# ATxmega384C3 device description
Architecture: AVR8_XMEGA; Family: AVR XMEGA
Registers are 8-bit, access not given, no defined reset value unless marked. A register's access mark holds for its fields unless they carry their own. Offsets are from the block's base; [hi:lo] are bit positions; lines under a group give offsets from that group; {n}, {i} and the like mark numbered series; 'fields as' and 'values as' point back to an identical list.

## DMA — DMA Controller
Instances: DMA 0x0100
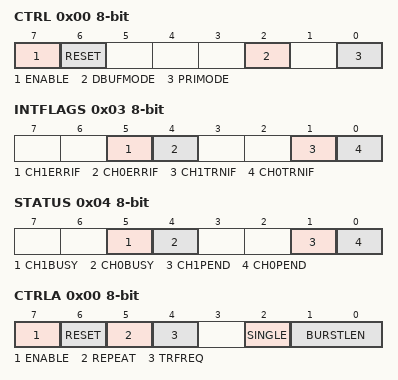
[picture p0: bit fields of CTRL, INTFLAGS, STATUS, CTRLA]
0x00 CTRL — Control
  [7] ENABLE
  [6] RESET — Software Reset
  [2] DBUFMODE — Double Buffering Mode
    0=DISABLED (Double buffering disabled); 1=CH01 (Double buffering enabled on channel 0/1)
  [0] PRIMODE — Channel Priority Mode
    0=RR01 (Round Robin); 1=CH01 (Channel 0 > channel 1)
0x03 INTFLAGS — Transfer Interrupt Status
  [5] CH1ERRIF — Channel 1 Block Transfer Error Interrupt Flag
  [4] CH0ERRIF — Channel 0 Block Transfer Error Interrupt Flag
  [1] CH1TRNIF — Channel 1 Transaction Complete Interrupt Flag
  [0] CH0TRNIF — Channel 0 Transaction Complete Interrupt Flag
0x04 STATUS
  [5] CH1BUSY — Channel 1 Block Transfer Busy
  [4] CH0BUSY — Channel 0 Block Transfer Busy
  [1] CH1PEND — Channel 1 Block Transfer Pending
  [0] CH0PEND — Channel 0 Block Transfer Pending
0x06 TEMP 16-bit — Temporary Register For 16-bit Access
0x10 CH0 group — DMA Channel 0
  0x00 CTRLA — Channel Control
    [7] ENABLE — Channel Enable
    [6] RESET — Channel Software Reset
    [5] REPEAT — Channel Repeat Mode
    [4] TRFREQ — Channel Transfer Request
    [2] SINGLE — Channel Single Shot Data Transfer
    [1:0] BURSTLEN — Channel Transfer Mode
      0=1BYTE (1-byte burst mode); 1=2BYTE (2-byte burst mode); 2=4BYTE (4-byte burst mode); 3=8BYTE (8-byte burst mode)
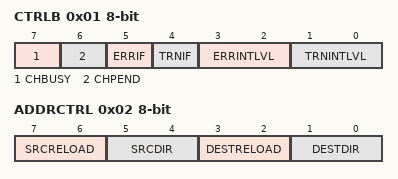
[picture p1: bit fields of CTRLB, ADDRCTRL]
  0x01 CTRLB — Channel Control
    [7] CHBUSY — Block Transfer Busy
    [6] CHPEND — Block Transfer Pending
    [5] ERRIF — Block Transfer Error Interrupt Flag
    [4] TRNIF — Transaction Complete Interrupt Flag
    [3:2] ERRINTLVL — Transfer Error Interrupt Level
      0=OFF (Interrupt disabled); 1=LO (Low level); 2=MED (Medium level); 3=HI (High level)
    [1:0] TRNINTLVL — Transaction Complete Interrupt Level
      values as ERRINTLVL
  0x02 ADDRCTRL — Address Control
    [7:6] SRCRELOAD — Channel Source Address Reload
      0=NONE (No reload); 1=BLOCK (Reload at end of block); 2=BURST (Reload at end of burst); 3=TRANSACTION (Reload at end of transaction)
    [5:4] SRCDIR — Channel Source Address Mode
      0=FIXED; 1=INC (Increment); 2=DEC (Decrement)
    [3:2] DESTRELOAD — Channel Destination Address Reload
      values as SRCRELOAD
    [1:0] DESTDIR — Channel Destination Address Mode
      0=FIXED; 1=INC (Increment); 2=DEC (Decrement)
  0x03 TRIGSRC — Channel Trigger Source
    [7:0] TRIGSRC
      0=OFF (Off software triggers only); 1=EVSYS_CH0 (Event System Channel 0); 2=EVSYS_CH1 (Event System Channel 1); 3=EVSYS_CH2 (Event System Channel 2); 4=AES; 16=ADCA_CH0 (ADCA Channel 0); 32=ADCB_CH0 (ADCB Channel 0); 64=TCC0_OVF (Timer/Counter C0 Overflow); 65=TCC0_ERR (Timer/Counter C0 Error); 66=TCC0_CCA (Timer/Counter C0 Compare or Capture A); 67=TCC0_CCB (Timer/Counter C0 Compare or Capture B); 68=TCC0_CCC (Timer/Counter C0 Compare or Capture C); 69=TCC0_CCD (Timer/Counter C0 Compare or Capture D); 70=TCC1_OVF (Timer/Counter C1 Overflow); 71=TCC1_ERR (Timer/Counter C1 Error); 72=TCC1_CCA (Timer/Counter C1 Compare or Capture A); 73=TCC1_CCB (Timer/Counter C1 Compare or Capture B); 74=SPIC (SPI C Transfer Complete); 75=USARTC0_RXC (USART C0 Receive Complete); 76=USARTC0_DRE (USART C0 Data Register Empty); 96=TCD0_OVF (Timer/Counter D0 Overflow); 97=TCD0_ERR (Timer/Counter D0 Error); 98=TCD0_CCA (Timer/Counter D0 Compare or Capture A); 99=TCD0_CCB (Timer/Counter D0 Compare or Capture B); 100=TCD0_CCC (Timer/Counter D0 Compare or Capture C); 101=TCD0_CCD (Timer/Counter D0 Compare or Capture D); 106=SPID (SPI D Transfer Complete); 107=USARTD0_RXC (USART D0 Receive Complete); 108=USARTD0_DRE (USART D0 Data Register Empty); 128=TCE0_OVF (Timer/Counter E0 Overflow); 129=TCE0_ERR (Timer/Counter E0 Error); 130=TCE0_CCA (Timer/Counter E0 Compare or Capture A); 131=TCE0_CCB (Timer/Counter E0 Compare or Capture B); 132=TCE0_CCC (Timer/Counter E0 Compare or Capture C); 133=TCE0_CCD (Timer/Counter E0 Compare or Capture D); 139=USARTE0_RXC (USART E0 Receive Complete); 140=USARTE0_DRE (USART E0 Data Register Empty); 160=TCF0_OVF (Timer/Counter F0 Overflow); 161=TCF0_ERR (Timer/Counter F0 Error); 162=TCF0_CCA (Timer/Counter F0 Compare or Capture A); 163=TCF0_CCB (Timer/Counter F0 Compare or Capture B); 164=TCF0_CCC (Timer/Counter F0 Compare or Capture C); 165=TCF0_CCD (Timer/Counter F0 Compare or Capture D)
  0x04 TRFCNT 16-bit — Channel Block Transfer Count
  0x06 REPCNT — Channel Repeat Count
  {0x8+j} SRCADDR{j} (j=0..2) — Channel Source Address {j}
  {0xC+j} DESTADDR{j} (j=0..2) — Channel Destination Address {j}
0x20 CH1 group — DMA Channel 1
  0x00 CTRLA — Channel Control
    fields as CH0.CTRLA
  0x01 CTRLB — Channel Control
    fields as CH0.CTRLB
  0x02 ADDRCTRL — Address Control
    fields as CH0.ADDRCTRL
  0x03 TRIGSRC — Channel Trigger Source
    fields as CH0.TRIGSRC
  0x04 TRFCNT 16-bit — Channel Block Transfer Count
  0x06 REPCNT — Channel Repeat Count
  {0x8+j} SRCADDR{j} (j=0..2) — Channel Source Address {j}
  {0xC+j} DESTADDR{j} (j=0..2) — Channel Destination Address {j}
